AUTOSAR XML (schema 4-0-3)
standard types defined: uint8, Boolean, UInt16, UInt32, UInt8
package /AUTOSAR_Platform/DataConstrs
  range DC_Boolean: raw 0..1
  range DC_UInt16: raw 0..65535
  range DC_UInt8: raw 0..255
package /PATAC/Facility/DataTypes/Implementation
  compu method COMPU_Boolean: 0=FALSE, 1=TRUE
  unit NoUnit: factor-si-to-unit=1, offset-si-to-unit=0
package /PATAC/MSM/ComponentTypes
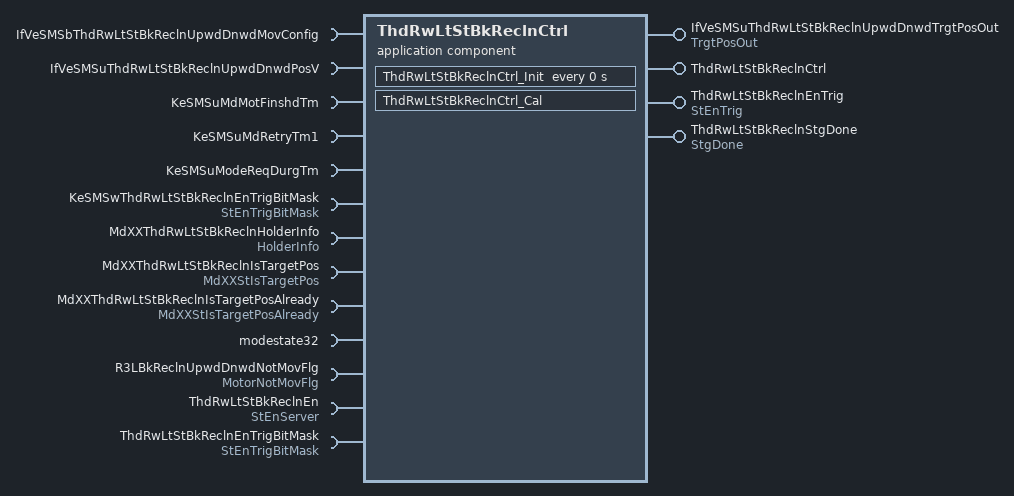
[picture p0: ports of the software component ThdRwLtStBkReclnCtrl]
  application sw component type ThdRwLtStBkReclnCtrl
    4 x provide port:
      IfVeSMSuThdRwLtStBkReclnUpwdDnwdTrgtPosOut: nonqueued-sender-com-spec=data-element=TrgtPosOut/Val, provided-interface=TrgtPosOut
      ThdRwLtStBkReclnCtrl: server-com-spec{operation=Cal, queue-length=1}, provided-interface=ThdRwLtStBkReclnCtrl
      ThdRwLtStBkReclnEnTrig: nonqueued-sender-com-spec{data-element=StEnTrig/Val, init-value=0}, provided-interface=StEnTrig
      ThdRwLtStBkReclnStgDone: nonqueued-sender-com-spec{data-element=StgDone/Val, init-value=0}, provided-interface=StgDone
    13 x require port:
      IfVeSMSbThdRwLtStBkReclnUpwdDnwdMovConfig: nonqueued-receiver-com-spec{data-element=IfVeSMSbThdRwLtStBkReclnUpwdDnwdMovConfig/Val, filter=data-filter-type=ALWAYS, init-value=0}, required-interface=IfVeSMSbThdRwLtStBkReclnUpwdDnwdMovConfig
      IfVeSMSuThdRwLtStBkReclnUpwdDnwdPosV: nonqueued-receiver-com-spec{data-element=IfVeSMSuThdRwLtStBkReclnUpwdDnwdPosV/Val, filter=data-filter-type=ALWAYS, init-value=0}, required-interface=IfVeSMSuThdRwLtStBkReclnUpwdDnwdPosV
      KeSMSuMdMotFinshdTm: parameter-require-com-spec{init-value=0, parameter=KeSMSuMdMotFinshdTm/Val}, required-interface=KeSMSuMdMotFinshdTm
      KeSMSuMdRetryTm1: parameter-require-com-spec{init-value=0, parameter=KeSMSuMdRetryTm1/Val}, required-interface=KeSMSuMdRetryTm1
      KeSMSuModeReqDurgTm: parameter-require-com-spec{init-value=0, parameter=KeSMSuModeReqDurgTm/Val}, required-interface=KeSMSuModeReqDurgTm
      KeSMSwThdRwLtStBkReclnEnTrigBitMask: parameter-require-com-spec{init-value=6153, parameter=StEnTrigBitMask/Val}, required-interface=StEnTrigBitMask
      MdXXThdRwLtStBkReclnHolderInfo: nonqueued-receiver-com-spec{data-element=HolderInfo/Val, filter=data-filter-type=ALWAYS, init-value=0}, required-interface=HolderInfo
      MdXXThdRwLtStBkReclnIsTargetPos: nonqueued-receiver-com-spec{data-element=MdXXStIsTargetPos/Val, filter=data-filter-type=ALWAYS, init-value=0}, required-interface=MdXXStIsTargetPos
      MdXXThdRwLtStBkReclnIsTargetPosAlready: nonqueued-receiver-com-spec{data-element=MdXXStIsTargetPosAlready/Val, filter=data-filter-type=ALWAYS, init-value=0}, required-interface=MdXXStIsTargetPosAlready
      modestate32: nonqueued-receiver-com-spec{data-element=modestate32/Val, filter=data-filter-type=ALWAYS, init-value=0}, required-interface=modestate32
      R3LBkReclnUpwdDnwdNotMovFlg: nonqueued-receiver-com-spec{data-element=MotorNotMovFlg/Val, filter=data-filter-type=ALWAYS, init-value=0}, required-interface=MotorNotMovFlg
      ThdRwLtStBkReclnEn: required-com-specs=[Clear, Get, Set], required-interface=StEnServer
      ThdRwLtStBkReclnEnTrigBitMask: nonqueued-receiver-com-spec{data-element=StEnTrigBitMask/Val, filter=data-filter-type=ALWAYS, init-value=0}, required-interface=StEnTrigBitMask
    behavior ThdRwLtStBkReclnCtrl_InternalBehavior
      operation invoked event OIT_ThdRwLtStBkReclnCtrl_Cal_ThdRwLtStBkReclnCtrl_Cal: start-on-event=ThdRwLtStBkReclnCtrl_Cal, operation=ThdRwLtStBkReclnCtrl.Cal
      timing event ThdRwLtStBkReclnCtrl_InitEvent: start-on-event=ThdRwLtStBkReclnCtrl_Init, period=0
      runnable ThdRwLtStBkReclnCtrl_Cal
        data-receive-point-by-arguments:
          8 x access:
            REC_IfVeSMSbThdRwLtStBkReclnUpwdDnwdMovConfig_Val: accessed-variable=IfVeSMSbThdRwLtStBkReclnUpwdDnwdMovConfig.Val
            REC_IfVeSMSuThdRwLtStBkReclnUpwdDnwdPosV_Val: accessed-variable=IfVeSMSuThdRwLtStBkReclnUpwdDnwdPosV.Val
            REC_MdXXThdRwLtStBkReclnHolderInfo_Val: accessed-variable=MdXXThdRwLtStBkReclnHolderInfo.Val
            REC_MdXXThdRwLtStBkReclnIsTargetPos_Val: accessed-variable=MdXXThdRwLtStBkReclnIsTargetPos.Val
            REC_MdXXThdRwLtStBkReclnIsTargetPosAlready_Val: accessed-variable=MdXXThdRwLtStBkReclnIsTargetPosAlready.Val
            REC_modestate32_Val: accessed-variable=modestate32.Val
            REC_R3LBkReclnUpwdDnwdNotMovFlg_Val: accessed-variable=R3LBkReclnUpwdDnwdNotMovFlg.Val
            REC_ThdRwLtStBkReclnEnTrigBitMask_Val: accessed-variable=ThdRwLtStBkReclnEnTrigBitMask.Val
        data-send-points:
          access SEND_IfVeSMSuThdRwLtStBkReclnUpwdDnwdTrgtPosOut_Val: accessed-variable=IfVeSMSuThdRwLtStBkReclnUpwdDnwdTrgtPosOut.Val
          access SEND_ThdRwLtStBkReclnEnTrig_Val: accessed-variable=ThdRwLtStBkReclnEnTrig.Val
          access SEND_ThdRwLtStBkReclnStgDone_Val: accessed-variable=ThdRwLtStBkReclnStgDone.Val
        4 x parameter access:
          PA_KeSMSuMdMotFinshdTm_Val: accessed-parameter=KeSMSuMdMotFinshdTm.Val
          PA_KeSMSuMdRetryTm1_Val: accessed-parameter=KeSMSuMdRetryTm1.Val
          PA_KeSMSuModeReqDurgTm_Val: accessed-parameter=KeSMSuModeReqDurgTm.Val
          PA_KeSMSwThdRwLtStBkReclnEnTrigBitMask_Val: accessed-parameter=KeSMSwThdRwLtStBkReclnEnTrigBitMask.Val
        sync call SC_ThdRwLtStBkReclnEn_Get: operation=ThdRwLtStBkReclnEn.Get, timeout=0
      runnable ThdRwLtStBkReclnCtrl_Init
        4 x parameter access:
          PA_KeSMSuMdMotFinshdTm_Val: accessed-parameter=KeSMSuMdMotFinshdTm.Val
          PA_KeSMSuMdRetryTm1_Val: accessed-parameter=KeSMSuMdRetryTm1.Val
          PA_KeSMSuModeReqDurgTm_Val: accessed-parameter=KeSMSuModeReqDurgTm.Val
          PA_KeSMSwThdRwLtStBkReclnEnTrigBitMask_Val: accessed-parameter=KeSMSwThdRwLtStBkReclnEnTrigBitMask.Val
  swc implementation ThdRwLtStBkReclnCtrl_Implementation: behavior=ThdRwLtStBkReclnCtrl_InternalBehavior
    code-descriptors:
      code Default: artifact-descriptors=autosar-engineering-object={short-label=Default, category=SWSRC}
package /PATAC/MSM/ModeAdjust/CalPortInterface
  parameter interface KeSMSuMdMotFinshdTm
    parameter data prototype Val: sw-calibration-access=READ-WRITE, type=UInt16
  parameter interface KeSMSuModeReqDurgTm
    parameter data prototype Val: sw-calibration-access=READ-WRITE, type=UInt16
  parameter interface StEnTrigBitMask
    parameter data prototype Val: sw-calibration-access=READ-WRITE, type=UInt32
package /PATAC/MSM/ModeAdjust/Interfaces
  sender receiver interface IfVeSMSuThdRwLtStBkReclnUpwdDnwdPosV: invalidation-policy{data-element=IfVeSMSuThdRwLtStBkReclnUpwdDnwdPosV/Val, handle-invalid=DONT-INVALIDATE}
    data Val: type=Boolean
package /PATAC/MSM/ModeAdjust/PortInterface
  client server interface StEnServer
    operation Clear
      arg data: type=UInt8, direction=IN, server-argument-impl-policy=USE-ARGUMENT-TYPE
    operation Get
      arg data: type=UInt32, direction=OUT, server-argument-impl-policy=USE-ARGUMENT-TYPE
    operation Set
      arg data: type=UInt8, direction=IN, server-argument-impl-policy=USE-ARGUMENT-TYPE
  client server interface ThdRwLtStBkReclnCtrl
    operation Cal
  9 x sender receiver interface:
    HolderInfo: invalidation-policy{data-element=HolderInfo/Val, handle-invalid=DONT-INVALIDATE}
      data Val: type=UInt32
    MdXXStIsTargetPos: invalidation-policy{data-element=MdXXStIsTargetPos/Val, handle-invalid=DONT-INVALIDATE}
      data Val: type=UInt32
    MdXXStIsTargetPosAlready: invalidation-policy{data-element=MdXXStIsTargetPosAlready/Val, handle-invalid=DONT-INVALIDATE}
      data Val: type=UInt32
    modestate32: invalidation-policy{data-element=modestate32/Val, handle-invalid=DONT-INVALIDATE}
      data Val: type=UInt32
    MotorNotMovFlg: invalidation-policy{data-element=MotorNotMovFlg/Val, handle-invalid=DONT-INVALIDATE}
      data Val: type=Boolean
    StEnTrig: invalidation-policy{data-element=StEnTrig/Val, handle-invalid=DONT-INVALIDATE}
      data Val: type=Boolean
    StEnTrigBitMask: invalidation-policy{data-element=StEnTrigBitMask/Val, handle-invalid=DONT-INVALIDATE}
      data Val: type=UInt32
    StgDone: invalidation-policy{data-element=StgDone/Val, handle-invalid=DONT-INVALIDATE}
      data Val: type=Boolean
    TrgtPosOut: invalidation-policy{data-element=TrgtPosOut/Val, handle-invalid=DONT-INVALIDATE}
      data Val: type=Boolean
package /PATAC/MSM/PortInterfaces
  parameter interface KeSMSuMdRetryTm1
    parameter data prototype Val: sw-calibration-access=READ-WRITE, type=UInt8
  sender receiver interface IfVeSMSbThdRwLtStBkReclnUpwdDnwdMovConfig: invalidation-policy{data-element=IfVeSMSbThdRwLtStBkReclnUpwdDnwdMovConfig/Val, handle-invalid=DONT-INVALIDATE}
    data Val: type=Boolean
